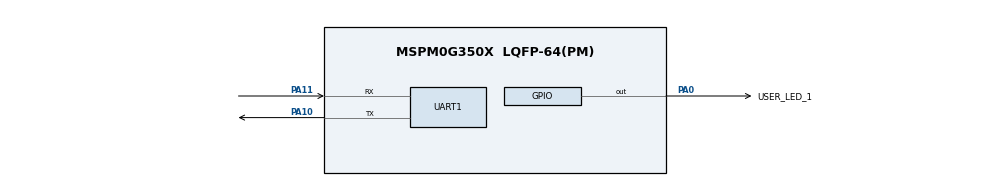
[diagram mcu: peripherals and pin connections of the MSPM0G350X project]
 //@cliArgs --device "MSPM0G350X" --package "LQFP-64(PM)" --part "Default"
// @cliArgs --board /ti/boards/LP_MSPM0G3507 --rtos nortos

/**
 * Import the modules used in this configuration.
 */
const GPIO  = scripting.addModule("/ti/driverlib/GPIO", {}, false);
const GPIO1 = GPIO.addInstance();
const UART  = scripting.addModule("/ti/driverlib/UART", {}, false);
const UART1 = UART.addInstance();

/**
 * Write custom configuration values to the imported modules.
 */
GPIO1.$name                                 = "GPIO_LEDS";
GPIO1.associatedPins[0].$name               = "USER_LED_1";
GPIO1.associatedPins[0].initialValue        = "SET";
GPIO1.associatedPins[0].assignedPort        = "PORTA";
GPIO1.associatedPins[0].assignedPortSegment = "Lower";
GPIO1.associatedPins[0].pin.$assign         = "PA0";

const Board = scripting.addModule("/ti/driverlib/Board", {}, false);

const SYSCTL = scripting.addModule("/ti/driverlib/SYSCTL", {}, false);

UART1.$name                    = "UART_0";
UART1.uartClkDiv               = "3";
UART1.enableExtend             = true;
UART1.enableIrda               = true;
UART1.setIrdaPulseLength       = 5;
UART1.uartClkDiv2              = "3";
UART1.enableFIFO               = true;
UART1.rxFifoThreshold          = "DL_UART_RX_FIFO_LEVEL_FULL";
UART1.enableMSBFirst           = true;
UART1.digitalGlitchFilter      = 3;
UART1.peripheral.$assign       = "UART0";
UART1.peripheral.rxPin.$assign = "PA11";
UART1.peripheral.txPin.$assign = "PA10";
UART1.txPinConfig.enableConfig = true;
UART1.txPinConfig.invert       = "ENABLE";
UART1.rxPinConfig.enableConfig = true;
UART1.rxPinConfig.invert       = "ENABLE";

SYSCTL.forceDefaultClkConfig = true;
